# STM32F429 register map
File version: 1.2
CPU: CM4 r1p0, little endian, no MPU, no FPU, 4 interrupt priority bits
Registers are 32-bit, read-write, reset 0x0 unless marked. A register's access mark holds for its fields unless they carry their own. Offsets are from the block's base; [hi:lo] are bit positions; {n}, {i} and the like mark numbered series; 'fields as' and 'values as' point back to an identical list.

## TIM9 — General purpose timers
Base 0x40014000
Same registers: TIM12 0x40001800
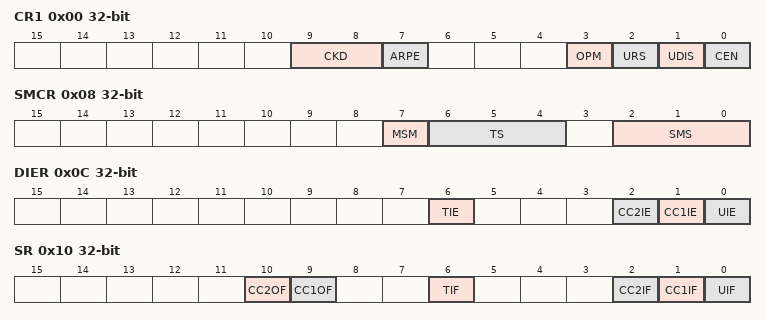
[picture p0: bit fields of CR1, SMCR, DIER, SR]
0x00 CR1 — control register 1
  [9:8] CKD — Clock division
    0=Div1 (t_DTS = t_CK_INT); 1=Div2 (t_DTS = 2 × t_CK_INT); 2=Div4 (t_DTS = 4 × t_CK_INT)
  [7] ARPE — Auto-reload preload enable
    0=Disabled (TIMx_APRR register is not buffered); 1=Enabled (TIMx_APRR register is buffered)
  [3] OPM — One-pulse mode
    0=Disabled (Counter is not stopped at update event); 1=Enabled (Counter stops counting at the next update event (clearing the CEN bit))
  [2] URS — Update request source
    0=AnyEvent (Any of counter overflow/underflow, setting UG, or update through slave mode, generates an update interrupt or DMA request); 1=CounterOnly (Only counter overflow/underflow generates an update interrupt or DMA request)
  [1] UDIS — Update disable
    0=Enabled (Update event enabled); 1=Disabled (Update event disabled)
  [0] CEN — Counter enable
    0=Disabled (Counter disabled); 1=Enabled (Counter enabled)
0x04 CR2 — control register 2
  [6:4] MMS — Master mode selection
0x08 SMCR — slave mode control register
  [7] MSM — Master/Slave mode
  [6:4] TS — Trigger selection
  [2:0] SMS — Slave mode selection
0x0C DIER — DMA/Interrupt enable register
  [6] TIE — Trigger interrupt enable
  [2] CC2IE — Capture/Compare 2 interrupt enable
  [1] CC1IE — Capture/Compare 1 interrupt enable
  [0] UIE — Update interrupt enable
    0=Disabled (Update interrupt disabled); 1=Enabled (Update interrupt enabled)
0x10 SR — status register
  [10] CC2OF — Capture/compare 2 overcapture flag
  [9] CC1OF — Capture/Compare 1 overcapture flag
  [6] TIF — Trigger interrupt flag
  [2] CC2IF — Capture/Compare 2 interrupt flag
  [1] CC1IF — Capture/compare 1 interrupt flag
  [0] UIF — Update interrupt flag
    0=Clear (No update occurred); 1=UpdatePending (Update interrupt pending.)
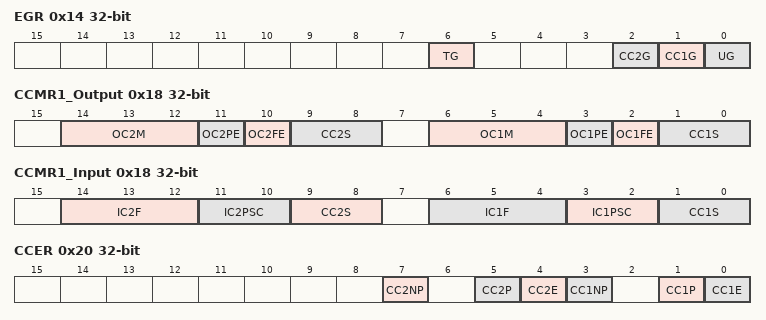
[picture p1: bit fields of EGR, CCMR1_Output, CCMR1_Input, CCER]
0x14 EGR wo — event generation register
  [6] TG — Trigger generation
  [2] CC2G — Capture/compare 2 generation
  [1] CC1G — Capture/compare 1 generation
  [0] UG — Update generation
    1=Update (Re-initializes the timer counter and generates an update of the registers.)
0x18 CCMR1_Output — capture/compare mode register 1 (output mode)
  [14:12] OC2M — Output Compare 2 mode
    0=Frozen (The comparison between the output compare register TIMx_CCRy and the counter TIMx_CNT has no effect on the outputs); 1=ActiveOnMatch (Set channel to active level on match. OCyREF signal is forced high when the counter matches the capture/compare register); 2=InactiveOnMatch (Set channel to inactive level on match. OCyREF signal is forced low when the counter matches the capture/compare register); 3=Toggle (OCyREF toggles when TIMx_CNT=TIMx_CCRy); 4=ForceInactive (OCyREF is forced low); 5=ForceActive (OCyREF is forced high); 6=PwmMode1 (In upcounting, channel is active as long as TIMx_CNT<TIMx_CCRy else inactive. In downcounting, channel is inactive as long as TIMx_CNT>TIMx_CCRy else active); 7=PwmMode2 (Inversely to PwmMode1)
  [11] OC2PE — Output Compare 2 preload enable
  [10] OC2FE — Output Compare 2 fast enable
  [9:8] CC2S — Capture/Compare 2 selection
  [6:4] OC1M — Output Compare 1 mode
    values as OC2M
  [3] OC1PE — Output Compare 1 preload enable
  [2] OC1FE — Output Compare 1 fast enable
  [1:0] CC1S — Capture/Compare 1 selection
0x18 CCMR1_Input (alternate view of CCMR1_Output) — capture/compare mode register 1 (input mode)
  [14:12] IC2F — Input capture 2 filter
  [11:10] IC2PSC — Input capture 2 prescaler
  [9:8] CC2S — Capture/Compare 2 selection
  [6:4] IC1F — Input capture 1 filter
  [3:2] IC1PSC — Input capture 1 prescaler
  [1:0] CC1S — Capture/Compare 1 selection
0x20 CCER — capture/compare enable register
  [7] CC2NP — Capture/Compare 2 output Polarity
  [5] CC2P — Capture/Compare 2 output Polarity
  [4] CC2E — Capture/Compare 2 output enable
  [3] CC1NP — Capture/Compare 1 output Polarity
  [1] CC1P — Capture/Compare 1 output Polarity
  [0] CC1E — Capture/Compare 1 output enable
0x24 CNT — counter
  [15:0] CNT — counter value
0x28 PSC — prescaler
  [15:0] PSC — Prescaler value
0x2C ARR — auto-reload register
  [15:0] ARR — Auto-reload value
{0x30+4i} CCR{i} (i=1..2) — capture/compare register
  [15:0] CCR — Capture/Compare value
